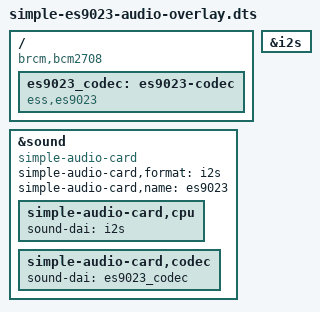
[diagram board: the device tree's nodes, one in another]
/*
 * Copyright (c) 2016 Clive Messer <clive.messer@digitaldreamtime.co.uk>
 *
 * This file is dual-licensed: you can use it either under the terms
 * of the GPL or the X11 license, at your option. Note that this dual
 * licensing only applies to this file, and not this project as a
 * whole.
 *
 *  a) This library is free software; you can redistribute it and/or
 *     modify it under the terms of the GNU General Public License as
 *     published by the Free Software Foundation; either version 2 of the
 *     License, or (at your option) any later version.
 *
 *     This library is distributed in the hope that it will be useful,
 *     but WITHOUT ANY WARRANTY; without even the implied warranty of
 *     MERCHANTABILITY or FITNESS FOR A PARTICULAR PURPOSE.  See the
 *     GNU General Public License for more details.
 *
 * Or, alternatively,
 *
 *  b) Permission is hereby granted, free of charge, to any person
 *     obtaining a copy of this software and associated documentation
 *     files (the "Software"), to deal in the Software without
 *     restriction, including without limitation the rights to use,
 *     copy, modify, merge, publish, distribute, sublicense, and/or
 *     sell copies of the Software, and to permit persons to whom the
 *     Software is furnished to do so, subject to the following
 *     conditions:
 *
 *     The above copyright notice and this permission notice shall be
 *     included in all copies or substantial portions of the Software.
 *
 *     THE SOFTWARE IS PROVIDED "AS IS", WITHOUT WARRANTY OF ANY KIND,
 *     EXPRESS OR IMPLIED, INCLUDING BUT NOT LIMITED TO THE WARRANTIES
 *     OF MERCHANTABILITY, FITNESS FOR A PARTICULAR PURPOSE AND
 *     NONINFRINGEMENT. IN NO EVENT SHALL THE AUTHORS OR COPYRIGHT
 *     HOLDERS BE LIABLE FOR ANY CLAIM, DAMAGES OR OTHER LIABILITY,
 *     WHETHER IN AN ACTION OF CONTRACT, TORT OR OTHERWISE, ARISING
 *     FROM, OUT OF OR IN CONNECTION WITH THE SOFTWARE OR THE USE OR
 *     OTHER DEALINGS IN THE SOFTWARE.
 */

/*
 * Definitions for a generic board or HAT using ESS Sabre ES9023 DAC
 *  eg. dtoverlay=simple-es9023-audio,384k,card_name="es9023"
 */

/dts-v1/;
/plugin/;

/ {
	compatible = "brcm,bcm2708";

	fragment@0 {
		target = <&i2s>;
		__overlay__ {
			status = "okay";
		};
	};

	fragment@1 {
		target-path = "/";
		__overlay__ {
			es9023_codec: es9023-codec {
				#sound-dai-cells = <0>;
				compatible = "ess,es9023";
				status = "okay";
			};
		};
	};

	fragment@2 {
		target = <&sound>;
		simple_audio_card: __overlay__ {
			compatible = "simple-audio-card";
			simple-audio-card,format = "i2s";
			simple-audio-card,name = "es9023";
			status = "okay";
			simple-audio-card,cpu {
				sound-dai = <&i2s>;
			};
			simple-audio-card,codec {
				sound-dai = <&es9023_codec>;
			};
		};
	};

	__overrides__ {
		384k = <&es9023_codec>,"es9023,384k?";
		card_name = <&simple_audio_card>,"simple-audio-card,name";
	};
};
